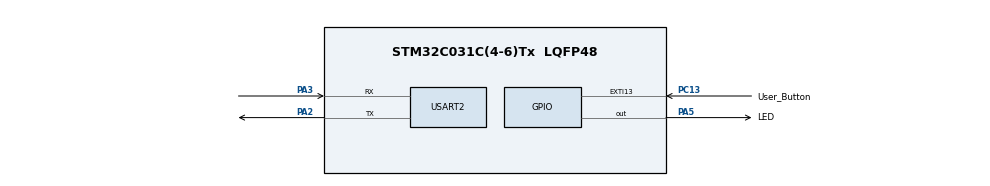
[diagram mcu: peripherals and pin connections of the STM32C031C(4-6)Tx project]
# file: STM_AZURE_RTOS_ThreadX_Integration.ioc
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Mcu.Family=STM32C0
Mcu.Name=STM32C031C(4-6)Tx
Mcu.Package=LQFP48
NVIC.EXTI4_15_IRQn=true\:0\:0\:false\:false\:true\:false\:true\:true\:true
NVIC.TIM16_IRQn=true\:3\:0\:false\:false\:true\:false\:false\:true\:true
NVIC.TimeBase=TIM16_IRQn
NVIC.TimeBaseIP=TIM16
PA2.Mode=Asynchronous
PA2.Signal=USART2_TX
PA3.Mode=Asynchronous
PA3.Signal=USART2_RX
PA5.GPIO_Label=LED
PA5.Signal=GPIO_Output
PC13.GPIO_Label=User_Button
PC13.Signal=GPXTI13
ProjectManager.HeapSize=0x200
ProjectManager.StackSize=0x400
ProjectManager.TargetToolchain=STM32CubeIDE
RCC.ADCFreq_Value=12000000
RCC.AHBFreq_Value=12000000
RCC.CortexFreq_Value=12000000
RCC.EXTERNAL_CLOCK_VALUE=12288000
RCC.HCLKFreq_Value=12000000
RCC.HSE_VALUE=8000000
RCC.HSI_VALUE=48000000
RCC.LSE_VALUE=32768
RCC.SYSCLKFreq_VALUE=12000000
USART2.VirtualMode-Asynchronous=VM_ASYNC
VP_SYS_VS_tim16.Mode=TIM16
VP_THREADX_VS_RTOSJjThreadXJjCoreJjDefault.Mode=Core_Default
board=custom

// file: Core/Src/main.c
/* USER CODE BEGIN Header */
/**
  ******************************************************************************
  * @file           : main.c
  * @brief          : Main program body
  ******************************************************************************
  * @attention
  *
  * Copyright (c) 2025 STMicroelectronics.
  * All rights reserved.
  *
  * This software is licensed under terms that can be found in the LICENSE file
  * in the root directory of this software component.
  * If no LICENSE file comes with this software, it is provided AS-IS.
  *
  ******************************************************************************
  */
/* USER CODE END Header */
#include "app_threadx.h"
#include "main.h"

UART_HandleTypeDef huart2;

void SystemClock_Config(void);
static void MX_GPIO_Init(void);
static void MX_USART2_UART_Init(void);

/* USER CODE BEGIN 0 */
void __io_putchar(char ch) {
    // Code to write character 'ch' on the UART
    HAL_UART_Transmit(&huart2, (uint8_t *)&ch, 1, 10);
}
/* USER CODE END 0 */

int main(void)
{

  /* MCU Configuration--------------------------------------------------------*/

  /* Reset of all peripherals, Initializes the Flash interface and the Systick. */
  HAL_Init();

  /* Configure the system clock */
  SystemClock_Config();

  /* Initialize all configured peripherals */
  MX_GPIO_Init();
  MX_USART2_UART_Init();

  MX_ThreadX_Init();

  /* We should never get here as control is now taken by the scheduler */

  /* Infinite loop */
  while (1)
  {

  }
}

void SystemClock_Config(void)
{
  RCC_OscInitTypeDef RCC_OscInitStruct = {0};
  RCC_ClkInitTypeDef RCC_ClkInitStruct = {0};

  /** Initializes the RCC Oscillators according to the specified parameters
  * in the RCC_OscInitTypeDef structure.
  */
  RCC_OscInitStruct.OscillatorType = RCC_OSCILLATORTYPE_HSI;
  RCC_OscInitStruct.HSIState = RCC_HSI_ON;
  RCC_OscInitStruct.HSIDiv = RCC_HSI_DIV4;
  RCC_OscInitStruct.HSICalibrationValue = RCC_HSICALIBRATION_DEFAULT;
  if (HAL_RCC_OscConfig(&RCC_OscInitStruct) != HAL_OK)
  {
    Error_Handler();
  }

  /** Initializes the CPU, AHB and APB buses clocks
  */
  RCC_ClkInitStruct.ClockType = RCC_CLOCKTYPE_HCLK|RCC_CLOCKTYPE_SYSCLK
                              |RCC_CLOCKTYPE_PCLK1;
  RCC_ClkInitStruct.SYSCLKSource = RCC_SYSCLKSOURCE_HSI;
  RCC_ClkInitStruct.SYSCLKDivider = RCC_SYSCLK_DIV1;
  RCC_ClkInitStruct.AHBCLKDivider = RCC_HCLK_DIV1;
  RCC_ClkInitStruct.APB1CLKDivider = RCC_APB1_DIV1;

  if (HAL_RCC_ClockConfig(&RCC_ClkInitStruct, FLASH_LATENCY_0) != HAL_OK)
  {
    Error_Handler();
  }
}

static void MX_USART2_UART_Init(void)
{

  huart2.Instance = USART2;
  huart2.Init.BaudRate = 115200;
  huart2.Init.WordLength = UART_WORDLENGTH_8B;
  huart2.Init.StopBits = UART_STOPBITS_1;
  huart2.Init.Parity = UART_PARITY_NONE;
  huart2.Init.Mode = UART_MODE_TX_RX;
  huart2.Init.HwFlowCtl = UART_HWCONTROL_NONE;
  huart2.Init.OverSampling = UART_OVERSAMPLING_16;
  huart2.Init.OneBitSampling = UART_ONE_BIT_SAMPLE_DISABLE;
  huart2.Init.ClockPrescaler = UART_PRESCALER_DIV1;
  huart2.AdvancedInit.AdvFeatureInit = UART_ADVFEATURE_NO_INIT;
  if (HAL_UART_Init(&huart2) != HAL_OK)
  {
    Error_Handler();
  }

}

static void MX_GPIO_Init(void)
{
  GPIO_InitTypeDef GPIO_InitStruct = {0};

  /* GPIO Ports Clock Enable */
  __HAL_RCC_GPIOC_CLK_ENABLE();
  __HAL_RCC_GPIOA_CLK_ENABLE();

  /*Configure GPIO pin Output Level */
  HAL_GPIO_WritePin(LED_GPIO_Port, LED_Pin, GPIO_PIN_RESET);

  /*Configure GPIO pin : User_Button_Pin */
  GPIO_InitStruct.Pin = User_Button_Pin;
  GPIO_InitStruct.Mode = GPIO_MODE_IT_RISING;
  GPIO_InitStruct.Pull = GPIO_NOPULL;
  HAL_GPIO_Init(User_Button_GPIO_Port, &GPIO_InitStruct);

  /*Configure GPIO pin : LED_Pin */
  GPIO_InitStruct.Pin = LED_Pin;
  GPIO_InitStruct.Mode = GPIO_MODE_OUTPUT_PP;
  GPIO_InitStruct.Pull = GPIO_NOPULL;
  GPIO_InitStruct.Speed = GPIO_SPEED_FREQ_LOW;
  HAL_GPIO_Init(LED_GPIO_Port, &GPIO_InitStruct);

  /* EXTI interrupt init*/
  HAL_NVIC_SetPriority(EXTI4_15_IRQn, 0, 0);
  HAL_NVIC_EnableIRQ(EXTI4_15_IRQn);

}

void HAL_TIM_PeriodElapsedCallback(TIM_HandleTypeDef *htim)
{
  if (htim->Instance == TIM16) {
    HAL_IncTick();
  }
}

void Error_Handler(void)
{
  __disable_irq();
  while (1)
  {
  }
}
